# RS1xxxx register map
Vendor: Silicon Lab Inc.; Series: ARMCM4; File version: 1.2
CPU: CM4 r1p0, little endian, MPU, FPU, 6 interrupt priority bits
Registers are 32-bit, read-write, reset 0x0 unless marked. A register's access mark holds for its fields unless they carry their own. Offsets are from the block's base; [hi:lo] are bit positions; lines under a group give offsets from that group; 'fields as' and 'values as' point back to an identical list.

## SYSRTC — SYSRTC Register structure
Base 0x24048C00
0x00 SYSRTC_IPVERSION ro reset 0x1 — Shows SYSRTC IPVERSION
  [31:0] IP_VERSION
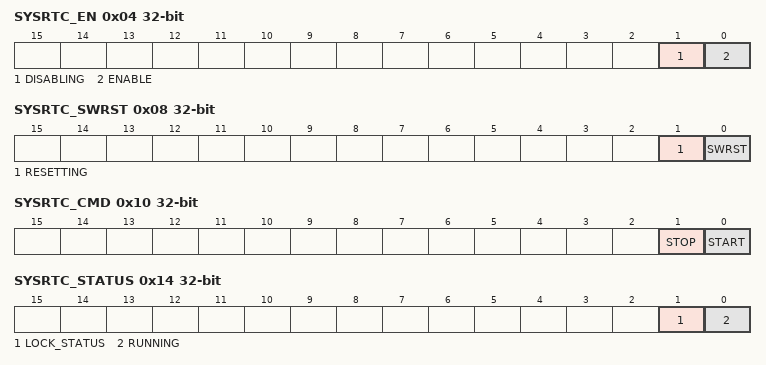
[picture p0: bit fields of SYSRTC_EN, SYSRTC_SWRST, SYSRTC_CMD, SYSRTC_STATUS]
0x04 SYSRTC_EN — SYSRTC Enable and disabling status
  [1] DISABLING ro — Disablement busy status. Set when EN cleared and cleared when the peripheral core reset is finished
  [0] ENABLE — SYSRTC Enable, Enable the SYSRTC by requesting Clock
0x08 SYSRTC_SWRST — SYSRTC software reset
  [1] RESETTING ro — Software reset busy status
  [0] SWRST wo — Software reset command
0x0C SYSRTC_CFG — SYSRTC configuration register
  [0] DEBUG_RUN — Debug Mode run Enable
0x10 SYSRTC_CMD wo — SYSRTC start or stop command register
  [1] STOP — Stop SYSRTC
  [0] START — Start SYSRTC
0x14 SYSRTC_STATUS ro — SYSRTC lock or running status register
  [1] LOCK_STATUS
  [0] RUNNING — SYSRTC running status
0x18 SYSRTC_CNT — SYSRTC counter value register
  [31:0] CNT — Counter value
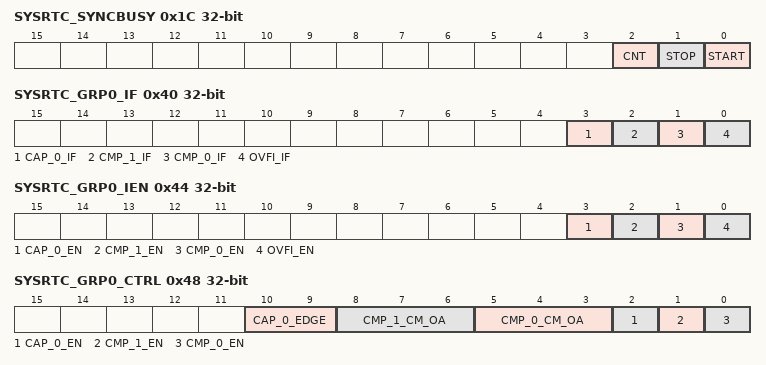
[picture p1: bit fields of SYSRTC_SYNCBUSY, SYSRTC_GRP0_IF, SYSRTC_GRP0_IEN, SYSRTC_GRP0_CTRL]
0x1C SYSRTC_SYNCBUSY ro
  [2] CNT — Sync busy for CNT bitfield
  [1] STOP — Sync busy for STOP bitfield
  [0] START — Sync busy for START bitfield
0x20 SYSRTC_LOCK wo — SYSRTC lock key configuration register
  [15:0] LOCK_KEY — Configuration Lock Key
0x40 SYSRTC_GRP0_IF — SYSRTC Group 0 interrupt flag register
  [3] CAP_0_IF — Capture 0 Interrupt Flag
  [2] CMP_1_IF — Compare 1 Interrupt Flag
  [1] CMP_0_IF — Compare 0 Interrupt Flag
  [0] OVFI_IF — Overflow Interrupt Flag
0x44 SYSRTC_GRP0_IEN — SYSRTC Group 0 interrupt enable register
  [3] CAP_0_EN — Capture 0 Interrupt Enable
  [2] CMP_1_EN — Compare 1 Interrupt Enable
  [1] CMP_0_EN — Compare 0 Interrupt Enable
  [0] OVFI_EN — Overflow Interrupt Enable
0x48 SYSRTC_GRP0_CTRL — SYSRTC Group 0 control register
  [10:9] CAP_0_EDGE — Capture 0 Edge Select
  [8:6] CMP_1_CM_OA — Compare 1 Compare Match Output Action
  [5:3] CMP_0_CM_OA — Compare 0 Compare Match Output Action
  [2] CAP_0_EN — Capture 0 Enable
  [1] CMP_1_EN — Compare 1 Enable
  [0] CMP_0_EN — Compare 0 Enable
0x4C SYSRTC_GRP0_CMP0VALUE — SYSRTC group 0 compare 0 value Register
  [31:0] CMP_0_VALUE — Compare 0 Value
0x50 SYSRTC_GRP0_CMP1VALUE — SYSRTC group 0 compare 1 value Register
  [31:0] CMP_1_VALUE — Compare 1 Value
0x54 SYSRTC_GRP0_CAP0VALUE ro — SYSRTC group 0 capture 0 value Register
  [31:0] CAP_0_VALUE — Capture 0 Value
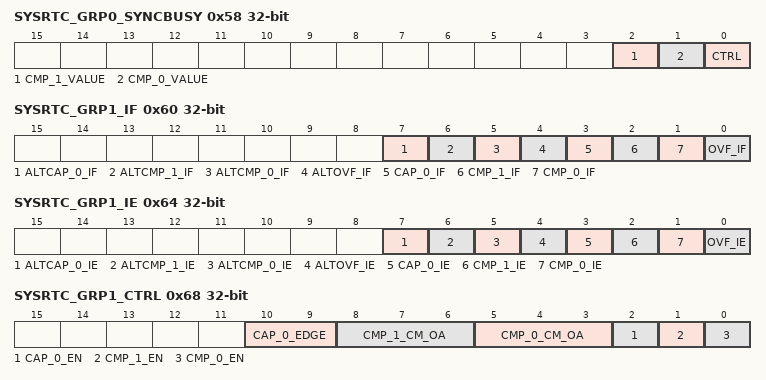
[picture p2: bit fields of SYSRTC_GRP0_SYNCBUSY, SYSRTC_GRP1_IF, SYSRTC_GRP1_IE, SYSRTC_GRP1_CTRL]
0x58 SYSRTC_GRP0_SYNCBUSY ro — SYSRTC group 0 sync busy status register
  [2] CMP_1_VALUE — Sync busy for CMP 1 VALUE register
  [1] CMP_0_VALUE — Sync busy for CMP 0 VALUE register
  [0] CTRL — Sync busy for CTRL register
0x60 SYSRTC_GRP1_IF — SYSRTC Group 1 interrupt flag register
  [7] ALTCAP_0_IF — Alternate Capture 0 interrupt Flag
  [6] ALTCMP_1_IF — Alternate Compare 1 interrupt Flag
  [5] ALTCMP_0_IF — Alternate Compare 0 interrupt Flag
  [4] ALTOVF_IF — Alternate Overflow Interrupt Flag
  [3] CAP_0_IF — Capture 0 Interrupt Flag
  [2] CMP_1_IF — Compare 1 Interrupt Flag
  [1] CMP_0_IF — Compare 0 Interrupt Flag
  [0] OVF_IF — Overflow Interrupt Flag
0x64 SYSRTC_GRP1_IE — SYSRTC Group 1 interrupt flag enable register
  [7] ALTCAP_0_IE — Alternate Capture 0 interrupt Enable
  [6] ALTCMP_1_IE — Alternate Compare 1 interrupt Enable
  [5] ALTCMP_0_IE — Alternate Compare 0 interrupt Enable
  [4] ALTOVF_IE — Alternate Overflow Interrupt Enable
  [3] CAP_0_IE — Capture 0 Interrupt Enable
  [2] CMP_1_IE — Compare 1 Interrupt Enable
  [1] CMP_0_IE — Compare 0 Interrupt Enable
  [0] OVF_IE — Overflow Interrupt Enable
0x68 SYSRTC_GRP1_CTRL — SYSRTC Group 1 control register
  fields as SYSRTC_GRP0_CTRL
0x6C SYSRTC_GRP1_CMP0VALUE — SYSRTC group 1 compare 0 value Register
  [31:0] CMP_0_VALUE — Compare 0 Value
0x70 SYSRTC_GRP1_CMP1VALUE — SYSRTC group 1 compare 1 value Register
  [31:0] CMP_1_VALUE — Compare 1 Value
0x74 SYSRTC_GRP1_CAP0VALUE ro — SYSRTC group 1 capture 0 value Register
  [31:0] CAP_0_VALUE — Capture 0 Value
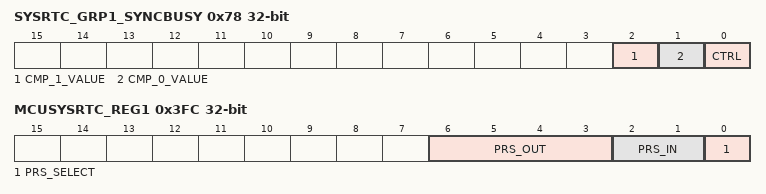
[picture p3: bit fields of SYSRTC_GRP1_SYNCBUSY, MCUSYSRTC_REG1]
0x78 SYSRTC_GRP1_SYNCBUSY ro — SYSRTC group 0 sync busy status register
  fields as SYSRTC_GRP0_SYNCBUSY
0x3FC MCUSYSRTC_REG1 — Input/Output Register
  [6:3] PRS_OUT ro — Output from SYSRTC module
  [2:1] PRS_IN wo — Input to SYSRTC module
  [0] PRS_SELECT — Selects whether PRS is from GPIO or register bits
